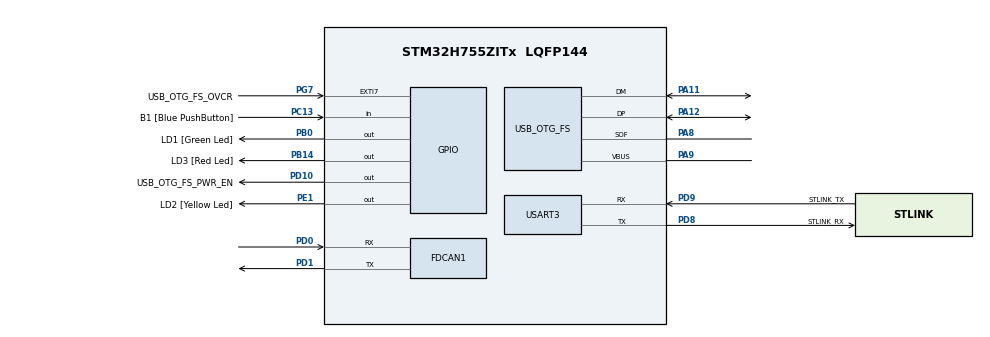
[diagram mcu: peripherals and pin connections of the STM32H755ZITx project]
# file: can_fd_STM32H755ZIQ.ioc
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Mcu.Family=STM32H7
RCC.CortexFreq_Value=64000000
PG7.PinAttribute=Free
PH0-OSC_IN\ (PH0).PinAttribute=CortexM7
PH0-OSC_IN\ (PH0).Signal=RCC_OSC_IN
PB14.GPIO_Label=LD3 [Red Led]
PC15-OSC32_OUT\ (OSC32_OUT).Mode=LSE-External-Oscillator
RCC.PLLFRACN=6144
PA11.Mode=Device_Only
PB0.GPIO_Label=LD1 [Green Led]
RCC.PLL2FRACN=0
PC13.GPIO_Label=B1 [Blue PushButton]
PB13.Signal=ETH_TXD1
PG13.Signal=ETH_TXD0
PD9.Mode=Asynchronous
PG11.Signal=ETH_TX_EN
ProjectManager.StackSize=0x400
USART3.VirtualMode-Asynchronous=VM_ASYNC
PA12.Signal=USB_OTG_FS_DP
RCC.HCLKFreq_Value=64000000
PD0.Signal=FDCAN1_RX
PD8.Signal=USART3_TX
PE1.Signal=GPIO_Output
PB0.PinAttribute=CortexM7
RCC.HSE_VALUE=8000000
RCC.DIVM2=1
RCC.DIVM1=1
NVIC2.PriorityGroup=NVIC_PRIORITYGROUP_4
FDCAN1.StdFiltersNbr=1
PD0.PinAttribute=CortexM7
PD1.GPIO_Speed=GPIO_SPEED_FREQ_VERY_HIGH
PD8.PinAttribute=CortexM7
VP_SYS_M4_VS_Systick.Mode=SysTick
PA8.Signal=USB_OTG_FS_SOF
NVIC1.FDCAN1_IT1_IRQn=true\:0\:0\:false\:false\:true\:true\:true
CortexM7.Pins=PB0,PB14
CortexM7.IPs=FATFS_M7\:I,FREERTOS_M7\:I,IWDG1\:I,RCC\:I,WWDG1\:I,DMA\:I,BDMA\:I,MDMA\:I,NVIC1\:I,ETH\:I,USART3\:I,USB_OTG_FS\:I,SYS\:I,CORTEX_M7\:I,DEBUG\:I,USB_DEVICE_M7\:I,USB_HOST_M7\:I,PDM2PCM_M7\:I,PWR\:I,RESMGR_UTILITY\:I,OPENAMP_M7\:I,VREFBUF\:I,FDCAN1\:I
PD10.PinAttribute=Free
FDCAN1.NominalTimeSeg2=20
FDCAN1.NominalTimeSeg1=59
RCC.APB3Freq_Value=64000000
PA7.PinAttribute=CortexM7
Mcu.Package=LQFP144
FDCAN1.RxFifo0ElmtsNbr=1
USB_OTG_FS.VirtualMode=Device_Only
PC14-OSC32_IN\ (OSC32_IN).Mode=LSE-External-Oscillator
RCC.APB4Freq_Value=64000000
RCC.FDCANCLockSelection=RCC_FDCANCLKSOURCE_PLL2
PC5.Signal=ETH_RXD1
PH0-OSC_IN\ (PH0).Mode=HSE-External-Clock-Source
RCC.SupplySource=PWR_DIRECT_SMPS_SUPPLY
PH1-OSC_OUT\ (PH1).PinAttribute=CortexM7
PB14.PinAttribute=CortexM7
RCC.DIVQ2=4
RCC.DIVQ1=3
PG7.Signal=GPXTI7
PD9.GPIO_Label=STLINK_TX
PA1.PinAttribute=CortexM7
PC13.Signal=GPIO_Input
FDCAN1.ProtocolException=ENABLE
CortexM4.Pins=PE1
PC4.Signal=ETH_RXD0
NVIC1.PriorityGroup=NVIC_PRIORITYGROUP_4
PD1.Signal=FDCAN1_TX
RCC.D2PPRE1=RCC_APB1_DIV2
PD9.Signal=USART3_RX
PA9.PinAttribute=CortexM7
PH1-OSC_OUT\ (PH1).Signal=RCC_OSC_OUT
PD0.GPIO_Speed=GPIO_SPEED_FREQ_VERY_HIGH
PG13.PinAttribute=CortexM7
PB13.PinAttribute=CortexM7
PD8.GPIO_Label=STLINK_RX
PD10.Signal=GPIO_Output
PA9.Mode=Activate_VBUS
PA12.PinAttribute=CortexM7
PA2.PinAttribute=CortexM7
ProjectManager.TargetToolchain=STM32CubeIDE
PC15-OSC32_OUT\ (OSC32_OUT).Signal=RCC_OSC32_OUT
PC14-OSC32_IN\ (OSC32_IN).PinAttribute=CortexM7
PA9.Signal=USB_OTG_FS_VBUS
RCC.DIVN2=20
RCC.DIVN1=18
PC4.PinAttribute=CortexM7
RCC.USBFreq_Value=50000000
PD10.GPIO_Label=USB_OTG_FS_PWR_EN
PD8.Mode=Asynchronous
PA1.Signal=ETH_REF_CLK
PB14.Signal=GPIO_Output
board=NUCLEO-H755ZI-Q
PG11.PinAttribute=CortexM7
PE1.GPIO_Label=LD2 [Yellow Led]
PD1.Mode=FDCAN_Activate
FDCAN1.AutoRetransmission=ENABLE
RCC.APB2Freq_Value=64000000
NVIC1.FDCAN1_IT0_IRQn=true\:0\:0\:false\:false\:true\:true\:true
PA11.PinAttribute=CortexM7
PG7.GPIO_Label=USB_OTG_FS_OVCR
RCC.ADCFreq_Value=80000000
PE1.PinAttribute=CortexM4
Mcu.Name=STM32H755ZITx
PD0.Mode=FDCAN_Activate
PA2.Signal=ETH_MDIO
PC13.PinAttribute=Free
FDCAN1.NominalSyncJumpWidth=8
RCC.SYSCLKFreq_VALUE=64000000
PA8.PinAttribute=CortexM7
PA12.Mode=Device_Only
PC14-OSC32_IN\ (OSC32_IN).Signal=RCC_OSC32_IN
PA11.Signal=USB_OTG_FS_DM
PD1.PinAttribute=CortexM7
ProjectManager.HeapSize=0x200
PD9.PinAttribute=CortexM7
PC15-OSC32_OUT\ (OSC32_OUT).PinAttribute=CortexM7
PC5.PinAttribute=CortexM7
PA8.Mode=Activate_SOF_FS
PC1.PinAttribute=CortexM7
RCC.APB1Freq_Value=32000000
PB0.Signal=GPIO_Output
FDCAN1.TxFifoQueueElmtsNbr=1
PC1.Signal=ETH_MDC
PA7.Signal=ETH_CRS_DV
CortexM4.IPs=FATFS_M4\:I,FREERTOS_M4\:I,IWDG2\:I,RCC,WWDG2\:I,DMA,BDMA,MDMA,NVIC2\:I,ETH,USART3,DEBUG,USB_DEVICE_M4\:I,USB_HOST_M4\:I,PDM2PCM_M4\:I,PWR,RESMGR_UTILITY,SYS_M4\:I,CORTEX_M4\:I,OPENAMP_M4\:I,VREFBUF

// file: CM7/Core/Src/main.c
/* USER CODE BEGIN Header */
/**
  ******************************************************************************
  * @file           : main.c
  * @brief          : Main program body
  ******************************************************************************
  * @attention
  *
  * <h2><center>&copy; Copyright (c) 2021 STMicroelectronics.
  * All rights reserved.</center></h2>
  *
  * This software component is licensed by ST under BSD 3-Clause license,
  * the "License"; You may not use this file except in compliance with the
  * License. You may obtain a copy of the License at:
  *                        opensource.org/licenses/BSD-3-Clause
  *
  ******************************************************************************
  */
/* USER CODE END Header */
#include <can_setting.h>
#include "main.h"

/* USER CODE BEGIN PD */

#ifndef HSEM_ID_0
#define HSEM_ID_0 (0U) /* HW semaphore 0*/
#endif
/* USER CODE END PD */

FDCAN_HandleTypeDef hfdcan1;

UART_HandleTypeDef huart3;

PCD_HandleTypeDef hpcd_USB_OTG_FS;

/* USER CODE BEGIN PV */
FDCAN_RxHeaderTypeDef RxHeader;
uint8_t RxData[64];
FDCAN_TxHeaderTypeDef TxHeader;
uint8_t TxData[64];

uint32_t systick;
/* USER CODE END PV */

void SystemClock_Config(void);
static void MX_GPIO_Init(void);
static void MX_USART3_UART_Init(void);
static void MX_USB_OTG_FS_PCD_Init(void);
static void MX_FDCAN1_Init(void);

int main(void)
{
  /* USER CODE BEGIN 1 */
	  uint32_t tick = 0;
	  uint16_t i=0;
  /* USER CODE END 1 */
/* USER CODE BEGIN Boot_Mode_Sequence_0 */
  int32_t timeout;
/* USER CODE END Boot_Mode_Sequence_0 */

/* USER CODE BEGIN Boot_Mode_Sequence_1 */
  /* Wait until CPU2 boots and enters in stop mode or timeout*/
  timeout = 0xFFFF;
  while((__HAL_RCC_GET_FLAG(RCC_FLAG_D2CKRDY) != RESET) && (timeout-- > 0));
  if ( timeout < 0 )
  {
  Error_Handler();
  }
/* USER CODE END Boot_Mode_Sequence_1 */
  /* MCU Configuration--------------------------------------------------------*/

  /* Reset of all peripherals, Initializes the Flash interface and the Systick. */
  HAL_Init();

  /* Configure the system clock */
  SystemClock_Config();
/* USER CODE BEGIN Boot_Mode_Sequence_2 */
/* When system initialization is finished, Cortex-M7 will release Cortex-M4 by means of
HSEM notification */
/*HW semaphore Clock enable*/
__HAL_RCC_HSEM_CLK_ENABLE();
/*Take HSEM */
HAL_HSEM_FastTake(HSEM_ID_0);
/*Release HSEM in order to notify the CPU2(CM4)*/
HAL_HSEM_Release(HSEM_ID_0,0);
/* wait until CPU2 wakes up from stop mode */
timeout = 0xFFFF;
while((__HAL_RCC_GET_FLAG(RCC_FLAG_D2CKRDY) == RESET) && (timeout-- > 0));
if ( timeout < 0 )
{
Error_Handler();
}
/* USER CODE END Boot_Mode_Sequence_2 */

  /* Initialize all configured peripherals */
  MX_GPIO_Init();
  MX_USART3_UART_Init();
  MX_USB_OTG_FS_PCD_Init();
  MX_FDCAN1_Init();
  /* USER CODE BEGIN 2 */

  fd_can_init();
  FDCAN_Config();
  /* USER CODE END 2 */

  /* Infinite loop */
  while (1)
  {
	  if(systick - tick > 50)
      {
    	  HAL_GPIO_TogglePin(LD1_GPIO_Port, LD1_Pin);
    	  tick = systick;
          if (HAL_FDCAN_AddMessageToTxFifoQ(&hfdcan1, &TxHeader, TxData) != HAL_OK)
    	         {
        	  HAL_GPIO_TogglePin(LD3_GPIO_Port, LD3_Pin);
    	         }
    		           Error_Handler();
   		         }
     	   TxData[1] = i>>8;
    	   TxData[0] = i++;
  }
}

void SystemClock_Config(void)
{
  RCC_OscInitTypeDef RCC_OscInitStruct = {0};
  RCC_ClkInitTypeDef RCC_ClkInitStruct = {0};

  /** Supply configuration update enable
  */
  HAL_PWREx_ConfigSupply(PWR_DIRECT_SMPS_SUPPLY);
  /** Configure the main internal regulator output voltage
  */
  __HAL_PWR_VOLTAGESCALING_CONFIG(PWR_REGULATOR_VOLTAGE_SCALE3);

  while(!__HAL_PWR_GET_FLAG(PWR_FLAG_VOSRDY)) {}
  /** Macro to configure the PLL clock source
  */
  __HAL_RCC_PLL_PLLSOURCE_CONFIG(RCC_PLLSOURCE_HSE);
  /** Initializes the RCC Oscillators according to the specified parameters
  * in the RCC_OscInitTypeDef structure.
  */
  RCC_OscInitStruct.OscillatorType = RCC_OSCILLATORTYPE_HSI|RCC_OSCILLATORTYPE_HSE;
  RCC_OscInitStruct.HSEState = RCC_HSE_BYPASS;
  RCC_OscInitStruct.HSIState = RCC_HSI_DIV1;
  RCC_OscInitStruct.HSICalibrationValue = RCC_HSICALIBRATION_DEFAULT;
  RCC_OscInitStruct.PLL.PLLState = RCC_PLL_ON;
  RCC_OscInitStruct.PLL.PLLSource = RCC_PLLSOURCE_HSE;
  RCC_OscInitStruct.PLL.PLLM = 1;
  RCC_OscInitStruct.PLL.PLLN = 18;
  RCC_OscInitStruct.PLL.PLLP = 2;
  RCC_OscInitStruct.PLL.PLLQ = 3;
  RCC_OscInitStruct.PLL.PLLR = 2;
  RCC_OscInitStruct.PLL.PLLRGE = RCC_PLL1VCIRANGE_3;
  RCC_OscInitStruct.PLL.PLLVCOSEL = RCC_PLL1VCOMEDIUM;
  RCC_OscInitStruct.PLL.PLLFRACN = 6144;
  if (HAL_RCC_OscConfig(&RCC_OscInitStruct) != HAL_OK)
  {
    Error_Handler();
  }
  /** Initializes the CPU, AHB and APB buses clocks
  */
  RCC_ClkInitStruct.ClockType = RCC_CLOCKTYPE_HCLK|RCC_CLOCKTYPE_SYSCLK
                              |RCC_CLOCKTYPE_PCLK1|RCC_CLOCKTYPE_PCLK2
                              |RCC_CLOCKTYPE_D3PCLK1|RCC_CLOCKTYPE_D1PCLK1;
  RCC_ClkInitStruct.SYSCLKSource = RCC_SYSCLKSOURCE_HSI;
  RCC_ClkInitStruct.SYSCLKDivider = RCC_SYSCLK_DIV1;
  RCC_ClkInitStruct.AHBCLKDivider = RCC_HCLK_DIV1;
  RCC_ClkInitStruct.APB3CLKDivider = RCC_APB3_DIV1;
  RCC_ClkInitStruct.APB1CLKDivider = RCC_APB1_DIV2;
  RCC_ClkInitStruct.APB2CLKDivider = RCC_APB2_DIV1;
  RCC_ClkInitStruct.APB4CLKDivider = RCC_APB4_DIV1;

  if (HAL_RCC_ClockConfig(&RCC_ClkInitStruct, FLASH_LATENCY_1) != HAL_OK)
  {
    Error_Handler();
  }
}

static void MX_FDCAN1_Init(void)
{

  hfdcan1.Instance = FDCAN1;
  hfdcan1.Init.FrameFormat = FDCAN_FRAME_CLASSIC;
  hfdcan1.Init.Mode = FDCAN_MODE_NORMAL;
  hfdcan1.Init.AutoRetransmission = ENABLE;
  hfdcan1.Init.TransmitPause = DISABLE;
  hfdcan1.Init.ProtocolException = ENABLE;
  hfdcan1.Init.NominalPrescaler = 1;
  hfdcan1.Init.NominalSyncJumpWidth = 8;
  hfdcan1.Init.NominalTimeSeg1 = 59;
  hfdcan1.Init.NominalTimeSeg2 = 20;
  hfdcan1.Init.DataPrescaler = 1;
  hfdcan1.Init.DataSyncJumpWidth = 1;
  hfdcan1.Init.DataTimeSeg1 = 1;
  hfdcan1.Init.DataTimeSeg2 = 1;
  hfdcan1.Init.MessageRAMOffset = 0;
  hfdcan1.Init.StdFiltersNbr = 1;
  hfdcan1.Init.ExtFiltersNbr = 0;
  hfdcan1.Init.RxFifo0ElmtsNbr = 1;
  hfdcan1.Init.RxFifo0ElmtSize = FDCAN_DATA_BYTES_8;
  hfdcan1.Init.RxFifo1ElmtsNbr = 0;
  hfdcan1.Init.RxFifo1ElmtSize = FDCAN_DATA_BYTES_8;
  hfdcan1.Init.RxBuffersNbr = 0;
  hfdcan1.Init.RxBufferSize = FDCAN_DATA_BYTES_8;
  hfdcan1.Init.TxEventsNbr = 0;
  hfdcan1.Init.TxBuffersNbr = 0;
  hfdcan1.Init.TxFifoQueueElmtsNbr = 1;
  hfdcan1.Init.TxFifoQueueMode = FDCAN_TX_FIFO_OPERATION;
  hfdcan1.Init.TxElmtSize = FDCAN_DATA_BYTES_8;
  if (HAL_FDCAN_Init(&hfdcan1) != HAL_OK)
  {
    Error_Handler();
  }

}

static void MX_USART3_UART_Init(void)
{

  huart3.Instance = USART3;
  huart3.Init.BaudRate = 115200;
  huart3.Init.WordLength = UART_WORDLENGTH_8B;
  huart3.Init.StopBits = UART_STOPBITS_1;
  huart3.Init.Parity = UART_PARITY_NONE;
  huart3.Init.Mode = UART_MODE_TX_RX;
  huart3.Init.HwFlowCtl = UART_HWCONTROL_NONE;
  huart3.Init.OverSampling = UART_OVERSAMPLING_16;
  huart3.Init.OneBitSampling = UART_ONE_BIT_SAMPLE_DISABLE;
  huart3.Init.ClockPrescaler = UART_PRESCALER_DIV1;
  huart3.AdvancedInit.AdvFeatureInit = UART_ADVFEATURE_NO_INIT;
  if (HAL_UART_Init(&huart3) != HAL_OK)
  {
    Error_Handler();
  }
  if (HAL_UARTEx_SetTxFifoThreshold(&huart3, UART_TXFIFO_THRESHOLD_1_8) != HAL_OK)
  {
    Error_Handler();
  }
  if (HAL_UARTEx_SetRxFifoThreshold(&huart3, UART_RXFIFO_THRESHOLD_1_8) != HAL_OK)
  {
    Error_Handler();
  }
  if (HAL_UARTEx_DisableFifoMode(&huart3) != HAL_OK)
  {
    Error_Handler();
  }

}

static void MX_USB_OTG_FS_PCD_Init(void)
{

  hpcd_USB_OTG_FS.Instance = USB_OTG_FS;
  hpcd_USB_OTG_FS.Init.dev_endpoints = 9;
  hpcd_USB_OTG_FS.Init.speed = PCD_SPEED_FULL;
  hpcd_USB_OTG_FS.Init.dma_enable = DISABLE;
  hpcd_USB_OTG_FS.Init.phy_itface = PCD_PHY_EMBEDDED;
  hpcd_USB_OTG_FS.Init.Sof_enable = DISABLE;
  hpcd_USB_OTG_FS.Init.low_power_enable = DISABLE;
  hpcd_USB_OTG_FS.Init.lpm_enable = DISABLE;
  hpcd_USB_OTG_FS.Init.battery_charging_enable = ENABLE;
  hpcd_USB_OTG_FS.Init.vbus_sensing_enable = ENABLE;
  hpcd_USB_OTG_FS.Init.use_dedicated_ep1 = DISABLE;
  if (HAL_PCD_Init(&hpcd_USB_OTG_FS) != HAL_OK)
  {
    Error_Handler();
  }

}

static void MX_GPIO_Init(void)
{
  GPIO_InitTypeDef GPIO_InitStruct = {0};

  /* GPIO Ports Clock Enable */
  __HAL_RCC_GPIOC_CLK_ENABLE();
  __HAL_RCC_GPIOH_CLK_ENABLE();
  __HAL_RCC_GPIOA_CLK_ENABLE();
  __HAL_RCC_GPIOB_CLK_ENABLE();
  __HAL_RCC_GPIOD_CLK_ENABLE();
  __HAL_RCC_GPIOG_CLK_ENABLE();

  /*Configure GPIO pin Output Level */
  HAL_GPIO_WritePin(GPIOB, LD1_Pin|LD3_Pin, GPIO_PIN_RESET);

  /*Configure GPIO pins : PC1 PC4 PC5 */
  GPIO_InitStruct.Pin = GPIO_PIN_1|GPIO_PIN_4|GPIO_PIN_5;
  GPIO_InitStruct.Mode = GPIO_MODE_AF_PP;
  GPIO_InitStruct.Pull = GPIO_NOPULL;
  GPIO_InitStruct.Speed = GPIO_SPEED_FREQ_LOW;
  GPIO_InitStruct.Alternate = GPIO_AF11_ETH;
  HAL_GPIO_Init(GPIOC, &GPIO_InitStruct);

  /*Configure GPIO pins : PA1 PA2 PA7 */
  GPIO_InitStruct.Pin = GPIO_PIN_1|GPIO_PIN_2|GPIO_PIN_7;
  GPIO_InitStruct.Mode = GPIO_MODE_AF_PP;
  GPIO_InitStruct.Pull = GPIO_NOPULL;
  GPIO_InitStruct.Speed = GPIO_SPEED_FREQ_LOW;
  GPIO_InitStruct.Alternate = GPIO_AF11_ETH;
  HAL_GPIO_Init(GPIOA, &GPIO_InitStruct);

  /*Configure GPIO pins : LD1_Pin LD3_Pin */
  GPIO_InitStruct.Pin = LD1_Pin|LD3_Pin;
  GPIO_InitStruct.Mode = GPIO_MODE_OUTPUT_PP;
  GPIO_InitStruct.Pull = GPIO_NOPULL;
  GPIO_InitStruct.Speed = GPIO_SPEED_FREQ_LOW;
  HAL_GPIO_Init(GPIOB, &GPIO_InitStruct);

  /*Configure GPIO pin : PB13 */
  GPIO_InitStruct.Pin = GPIO_PIN_13;
  GPIO_InitStruct.Mode = GPIO_MODE_AF_PP;
  GPIO_InitStruct.Pull = GPIO_NOPULL;
  GPIO_InitStruct.Speed = GPIO_SPEED_FREQ_LOW;
  GPIO_InitStruct.Alternate = GPIO_AF11_ETH;
  HAL_GPIO_Init(GPIOB, &GPIO_InitStruct);

  /*Configure GPIO pins : PG11 PG13 */
  GPIO_InitStruct.Pin = GPIO_PIN_11|GPIO_PIN_13;
  GPIO_InitStruct.Mode = GPIO_MODE_AF_PP;
  GPIO_InitStruct.Pull = GPIO_NOPULL;
  GPIO_InitStruct.Speed = GPIO_SPEED_FREQ_LOW;
  GPIO_InitStruct.Alternate = GPIO_AF11_ETH;
  HAL_GPIO_Init(GPIOG, &GPIO_InitStruct);

}

void Error_Handler(void)
{
  /* USER CODE BEGIN Error_Handler_Debug */
  /* User can add his own implementation to report the HAL error return state */
//  __disable_irq();
//  while (1)
//  {
//  }
  /* USER CODE END Error_Handler_Debug */
}

/************************ (C) COPYRIGHT STMicroelectronics *****END OF FILE****/
